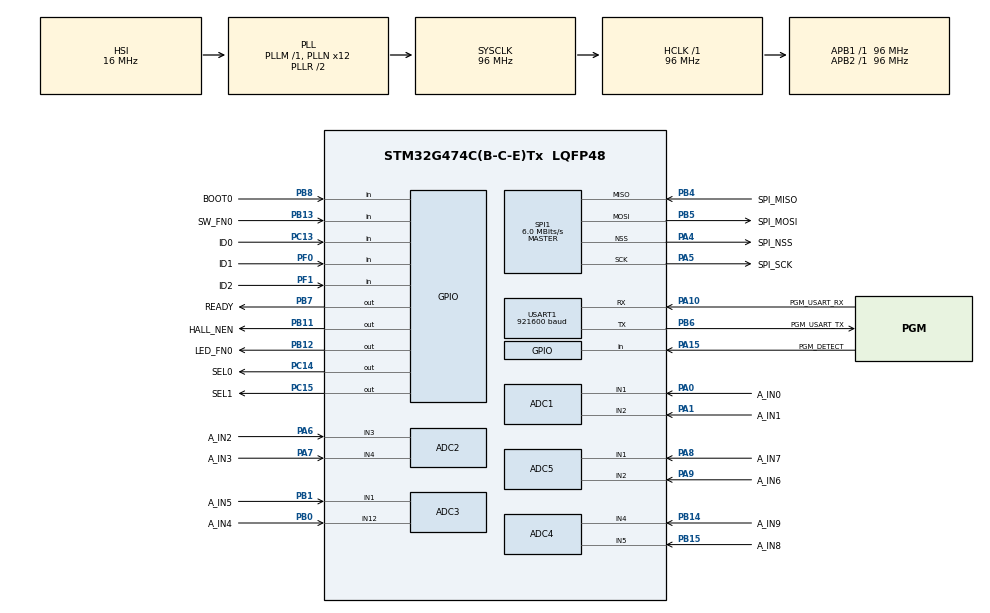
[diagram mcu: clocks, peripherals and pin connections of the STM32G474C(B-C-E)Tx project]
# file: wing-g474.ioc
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ADC1.Channel-1\#ChannelRegularConversion=ADC_CHANNEL_1
ADC1.EnableAnalogWatchDog1=false
ADC1.NbrOfConversion=1
ADC1.NbrOfConversionFlag=1
ADC1.OffsetNumber-1\#ChannelRegularConversion=ADC_OFFSET_NONE
ADC1.Rank-1\#ChannelRegularConversion=1
ADC1.SamplingTime-1\#ChannelRegularConversion=ADC_SAMPLETIME_2CYCLES_5
ADC1.master=1
ADC2.Channel-1\#ChannelRegularConversion=ADC_CHANNEL_3
ADC2.NbrOfConversionFlag=1
ADC2.OffsetNumber-1\#ChannelRegularConversion=ADC_OFFSET_NONE
ADC2.Rank-1\#ChannelRegularConversion=1
ADC2.SamplingTime-1\#ChannelRegularConversion=ADC_SAMPLETIME_2CYCLES_5
ADC3.Channel-0\#ChannelRegularConversion=ADC_CHANNEL_1
ADC3.NbrOfConversionFlag=1
ADC3.OffsetNumber-0\#ChannelRegularConversion=ADC_OFFSET_NONE
ADC3.Rank-0\#ChannelRegularConversion=1
ADC3.SamplingTime-0\#ChannelRegularConversion=ADC_SAMPLETIME_2CYCLES_5
ADC3.master=1
ADC4.Channel-0\#ChannelRegularConversion=ADC_CHANNEL_4
ADC4.NbrOfConversionFlag=1
ADC4.OffsetNumber-0\#ChannelRegularConversion=ADC_OFFSET_NONE
ADC4.Rank-0\#ChannelRegularConversion=1
ADC4.SamplingTime-0\#ChannelRegularConversion=ADC_SAMPLETIME_2CYCLES_5
ADC5.Channel-0\#ChannelRegularConversion=ADC_CHANNEL_1
ADC5.NbrOfConversionFlag=1
ADC5.OffsetNumber-0\#ChannelRegularConversion=ADC_OFFSET_NONE
ADC5.Rank-0\#ChannelRegularConversion=1
ADC5.SamplingTime-0\#ChannelRegularConversion=ADC_SAMPLETIME_2CYCLES_5
Dma.ADC1.0.Direction=DMA_PERIPH_TO_MEMORY
Dma.ADC1.0.EventEnable=DISABLE
Dma.ADC1.0.Instance=DMA1_Channel1
Dma.ADC1.0.MemDataAlignment=DMA_MDATAALIGN_HALFWORD
Dma.ADC1.0.MemInc=DMA_MINC_ENABLE
Dma.ADC1.0.Mode=DMA_CIRCULAR
Dma.ADC1.0.PeriphDataAlignment=DMA_PDATAALIGN_HALFWORD
Dma.ADC1.0.PeriphInc=DMA_PINC_DISABLE
Dma.ADC1.0.Polarity=HAL_DMAMUX_REQ_GEN_RISING
Dma.ADC1.0.Priority=DMA_PRIORITY_LOW
Dma.ADC1.0.RequestNumber=1
Dma.ADC1.0.SignalID=NONE
Dma.ADC1.0.SyncEnable=DISABLE
Dma.ADC1.0.SyncPolarity=HAL_DMAMUX_SYNC_NO_EVENT
Dma.ADC1.0.SyncRequestNumber=1
Dma.ADC1.0.SyncSignalID=NONE
Dma.ADC2.1.Direction=DMA_PERIPH_TO_MEMORY
Dma.ADC2.1.EventEnable=DISABLE
Dma.ADC2.1.Instance=DMA1_Channel2
Dma.ADC2.1.MemDataAlignment=DMA_MDATAALIGN_HALFWORD
Dma.ADC2.1.MemInc=DMA_MINC_ENABLE
Dma.ADC2.1.Mode=DMA_CIRCULAR
Dma.ADC2.1.PeriphDataAlignment=DMA_PDATAALIGN_HALFWORD
Dma.ADC2.1.PeriphInc=DMA_PINC_DISABLE
Dma.ADC2.1.Polarity=HAL_DMAMUX_REQ_GEN_RISING
Dma.ADC2.1.Priority=DMA_PRIORITY_LOW
Dma.ADC2.1.RequestNumber=1
Dma.ADC2.1.SignalID=NONE
Dma.ADC2.1.SyncEnable=DISABLE
Dma.ADC2.1.SyncPolarity=HAL_DMAMUX_SYNC_NO_EVENT
Dma.ADC2.1.SyncRequestNumber=1
Dma.ADC2.1.SyncSignalID=NONE
Dma.ADC3.2.Direction=DMA_PERIPH_TO_MEMORY
Dma.ADC3.2.EventEnable=DISABLE
Dma.ADC3.2.Instance=DMA1_Channel3
Dma.ADC3.2.MemDataAlignment=DMA_MDATAALIGN_HALFWORD
Dma.ADC3.2.MemInc=DMA_MINC_ENABLE
Dma.ADC3.2.Mode=DMA_CIRCULAR
Dma.ADC3.2.PeriphDataAlignment=DMA_PDATAALIGN_HALFWORD
Dma.ADC3.2.PeriphInc=DMA_PINC_DISABLE
Dma.ADC3.2.Polarity=HAL_DMAMUX_REQ_GEN_RISING
Dma.ADC3.2.Priority=DMA_PRIORITY_LOW
Dma.ADC3.2.RequestNumber=1
Dma.ADC3.2.SignalID=NONE
Dma.ADC3.2.SyncEnable=DISABLE
Dma.ADC3.2.SyncPolarity=HAL_DMAMUX_SYNC_NO_EVENT
Dma.ADC3.2.SyncRequestNumber=1
Dma.ADC3.2.SyncSignalID=NONE
Dma.ADC4.3.Direction=DMA_PERIPH_TO_MEMORY
Dma.ADC4.3.EventEnable=DISABLE
Dma.ADC4.3.Instance=DMA1_Channel4
Dma.ADC4.3.MemDataAlignment=DMA_MDATAALIGN_HALFWORD
Dma.ADC4.3.MemInc=DMA_MINC_ENABLE
Dma.ADC4.3.Mode=DMA_CIRCULAR
Dma.ADC4.3.PeriphDataAlignment=DMA_PDATAALIGN_HALFWORD
Dma.ADC4.3.PeriphInc=DMA_PINC_DISABLE
Dma.ADC4.3.Polarity=HAL_DMAMUX_REQ_GEN_RISING
Dma.ADC4.3.Priority=DMA_PRIORITY_LOW
Dma.ADC4.3.RequestNumber=1
Dma.ADC4.3.SignalID=NONE
Dma.ADC4.3.SyncEnable=DISABLE
Dma.ADC4.3.SyncPolarity=HAL_DMAMUX_SYNC_NO_EVENT
Dma.ADC4.3.SyncRequestNumber=1
Dma.ADC4.3.SyncSignalID=NONE
Dma.ADC5.4.Direction=DMA_PERIPH_TO_MEMORY
Dma.ADC5.4.EventEnable=DISABLE
Dma.ADC5.4.Instance=DMA1_Channel5
Dma.ADC5.4.MemDataAlignment=DMA_MDATAALIGN_HALFWORD
Dma.ADC5.4.MemInc=DMA_MINC_ENABLE
Dma.ADC5.4.Mode=DMA_CIRCULAR
Dma.ADC5.4.PeriphDataAlignment=DMA_PDATAALIGN_HALFWORD
Dma.ADC5.4.PeriphInc=DMA_PINC_DISABLE
Dma.ADC5.4.Polarity=HAL_DMAMUX_REQ_GEN_RISING
Dma.ADC5.4.Priority=DMA_PRIORITY_LOW
Dma.ADC5.4.RequestNumber=1
Dma.ADC5.4.SignalID=NONE
Dma.ADC5.4.SyncEnable=DISABLE
Dma.ADC5.4.SyncPolarity=HAL_DMAMUX_SYNC_NO_EVENT
Dma.ADC5.4.SyncRequestNumber=1
Dma.ADC5.4.SyncSignalID=NONE
Dma.Request0=ADC1
Dma.Request1=ADC2
Dma.Request2=ADC3
Dma.Request3=ADC4
Dma.Request4=ADC5
Mcu.Family=STM32G4
Mcu.Name=STM32G474C(B-C-E)Tx
Mcu.Package=LQFP48
NVIC.DMA1_Channel1_IRQn=true\:0\:0\:false\:false\:true\:false\:true\:true
NVIC.DMA1_Channel2_IRQn=true\:0\:0\:false\:false\:true\:false\:true\:true
NVIC.DMA1_Channel3_IRQn=true\:0\:0\:false\:false\:true\:false\:true\:true
NVIC.DMA1_Channel4_IRQn=true\:0\:0\:false\:false\:true\:false\:true\:true
NVIC.DMA1_Channel5_IRQn=true\:0\:0\:false\:false\:true\:false\:true\:true
NVIC.PriorityGroup=NVIC_PRIORITYGROUP_4
NVIC.USART1_IRQn=true\:0\:0\:false\:false\:true\:true\:true\:true
PA0.GPIO_Label=A_IN0
PA0.Mode=IN1-Single-Ended
PA0.Signal=ADC1_IN1
PA1.GPIO_Label=A_IN1
PA1.Mode=IN2-Single-Ended
PA1.Signal=ADC1_IN2
PA10.GPIO_Label=PGM_USART_RX
PA10.Mode=Asynchronous
PA10.Signal=USART1_RX
PA13.Mode=Trace_Asynchronous_SW
PA13.Signal=SYS_JTMS-SWDIO
PA14.Mode=Trace_Asynchronous_SW
PA14.Signal=SYS_JTCK-SWCLK
PA15.GPIO_Label=PGM_DETECT
PA15.GPIO_PuPd=GPIO_PULLUP
PA15.Signal=GPIO_Input
PA4.GPIO_Label=SPI_NSS
PA4.Mode=NSS_Signal_Hard_Output
PA4.Signal=SPI1_NSS
PA5.GPIO_Label=SPI_SCK
PA5.Mode=Full_Duplex_Master
PA5.Signal=SPI1_SCK
PA6.GPIO_Label=A_IN2
PA6.Mode=IN3-Single-Ended
PA6.Signal=ADC2_IN3
PA7.GPIO_Label=A_IN3
PA7.Mode=IN4-Single-Ended
PA7.Signal=ADC2_IN4
PA8.GPIO_Label=A_IN7
PA8.Mode=IN1-Single-Ended
PA8.Signal=ADC5_IN1
PA9.GPIO_Label=A_IN6
PA9.Mode=IN2-Single-Ended
PA9.Signal=ADC5_IN2
PB0.GPIO_Label=A_IN4
PB0.Mode=IN12-Single-Ended
PB0.Signal=ADC3_IN12
PB1.GPIO_Label=A_IN5
PB1.Mode=IN1-Single-Ended
PB1.Signal=ADC3_IN1
PB11.GPIO_Label=HALL_NEN
PB11.GPIO_ModeDefaultOutputPP=GPIO_MODE_OUTPUT_PP
PB11.GPIO_PuPd=GPIO_NOPULL
PB11.PinState=GPIO_PIN_SET
PB11.Signal=GPIO_Output
PB12.GPIO_Label=LED_FN0
PB12.Signal=GPIO_Output
PB13.GPIO_Label=SW_FN0
PB13.GPIO_PuPd=GPIO_PULLUP
PB13.Signal=GPIO_Input
PB14.GPIO_Label=A_IN9
PB14.Mode=IN4-Single-Ended
PB14.Signal=ADC4_IN4
PB15.GPIO_Label=A_IN8
PB15.Mode=IN5-Single-Ended
PB15.Signal=ADC4_IN5
PB3.Mode=Trace_Asynchronous_SW
PB3.Signal=SYS_JTDO-SWO
PB4.GPIO_Label=SPI_MISO
PB4.Mode=Full_Duplex_Master
PB4.Signal=SPI1_MISO
PB5.GPIO_Label=SPI_MOSI
PB5.Mode=Full_Duplex_Master
PB5.Signal=SPI1_MOSI
PB6.GPIO_Label=PGM_USART_TX
PB6.Mode=Asynchronous
PB6.Signal=USART1_TX
PB7.GPIO_Label=READY
PB7.Signal=GPIO_Output
PB8-BOOT0.GPIO_Label=BOOT0
PB8-BOOT0.Signal=GPIO_Input
PC13.GPIO_Label=ID0
PC13.Signal=GPIO_Input
PC14-OSC32_IN.GPIO_Label=SEL0
PC14-OSC32_IN.Signal=GPIO_Output
PC15-OSC32_OUT.GPIO_Label=SEL1
PC15-OSC32_OUT.Signal=GPIO_Output
PF0-OSC_IN.GPIO_Label=ID1
PF0-OSC_IN.Signal=GPIO_Input
PF1-OSC_OUT.GPIO_Label=ID2
PF1-OSC_OUT.Signal=GPIO_Input
ProjectManager.HeapSize=0x200
ProjectManager.StackSize=0x400
ProjectManager.TargetToolchain=CMake
RCC.ADC12Freq_Value=96000000
RCC.ADC345Freq_Value=96000000
RCC.AHBFreq_Value=96000000
RCC.APB1Freq_Value=96000000
RCC.APB1TimFreq_Value=96000000
RCC.APB2Freq_Value=96000000
RCC.APB2TimFreq_Value=96000000
RCC.CortexFreq_Value=96000000
RCC.EXTERNAL_CLOCK_VALUE=12288000
RCC.HCLKFreq_Value=96000000
RCC.HSE_VALUE=8000000
RCC.HSI48_VALUE=48000000
RCC.HSI_VALUE=16000000
RCC.LSE_VALUE=32768
RCC.PLLN=12
RCC.SYSCLKFreq_VALUE=96000000
RCC.SYSCLKSource=RCC_SYSCLKSOURCE_PLLCLK
RCC.USBFreq_Value=96000000
RCC.VCOOutputFreq_Value=192000000
SPI1.BaudRatePrescaler=SPI_BAUDRATEPRESCALER_16
SPI1.CRCCalculation=SPI_CRCCALCULATION_ENABLE
SPI1.CRCLength=SPI_CRC_LENGTH_16BIT
SPI1.CalculateBaudRate=6.0 MBits/s
SPI1.DataSize=SPI_DATASIZE_16BIT
SPI1.Direction=SPI_DIRECTION_2LINES
SPI1.Mode=SPI_MODE_MASTER
SPI1.NSSPMode=SPI_NSS_PULSE_DISABLE
SPI1.VirtualNSS=VM_NSSHARD
SPI1.VirtualType=VM_MASTER
USART1.BaudRate=921600
USART1.VirtualMode-Asynchronous=VM_ASYNC
VP_SYS_VS_DBSignals.Mode=DisableDeadBatterySignals
board=custom

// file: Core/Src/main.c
/* USER CODE BEGIN Header */
/**
  ******************************************************************************
  * @file           : main.c
  * @brief          : Main program body
  ******************************************************************************
  * @attention
  *
  * Copyright (c) 2026 STMicroelectronics.
  * All rights reserved.
  *
  * This software is licensed under terms that can be found in the LICENSE file
  * in the root directory of this software component.
  * If no LICENSE file comes with this software, it is provided AS-IS.
  *
  ******************************************************************************
  */
/* USER CODE END Header */
#include "main.h"

/* USER CODE BEGIN Includes */
#include "app/app.h"
/* USER CODE END Includes */

ADC_HandleTypeDef hadc1;
ADC_HandleTypeDef hadc2;
ADC_HandleTypeDef hadc3;
ADC_HandleTypeDef hadc4;
ADC_HandleTypeDef hadc5;
DMA_HandleTypeDef hdma_adc1;
DMA_HandleTypeDef hdma_adc2;
DMA_HandleTypeDef hdma_adc3;
DMA_HandleTypeDef hdma_adc4;
DMA_HandleTypeDef hdma_adc5;

SPI_HandleTypeDef hspi1;

UART_HandleTypeDef huart1;

void SystemClock_Config(void);
static void MX_GPIO_Init(void);
static void MX_DMA_Init(void);
static void MX_ADC1_Init(void);
static void MX_ADC2_Init(void);
static void MX_ADC3_Init(void);
static void MX_ADC4_Init(void);
static void MX_ADC5_Init(void);
static void MX_SPI1_Init(void);
static void MX_USART1_UART_Init(void);

int main(void)
{

  /* MCU Configuration--------------------------------------------------------*/

  /* Reset of all peripherals, Initializes the Flash interface and the Systick. */
  HAL_Init();

  /* Configure the system clock */
  SystemClock_Config();

  /* Initialize all configured peripherals */
  MX_GPIO_Init();
  MX_DMA_Init();
  MX_ADC1_Init();
  MX_ADC2_Init();
  MX_ADC3_Init();
  MX_ADC4_Init();
  MX_ADC5_Init();
  MX_SPI1_Init();
  MX_USART1_UART_Init();
  /* USER CODE BEGIN 2 */
  main_init();
  /* USER CODE END 2 */

  /* Infinite loop */
  while (1)
  {

    /* USER CODE BEGIN 3 */
    main_task();
  }
  /* USER CODE END 3 */
}

void SystemClock_Config(void)
{
  RCC_OscInitTypeDef RCC_OscInitStruct = {0};
  RCC_ClkInitTypeDef RCC_ClkInitStruct = {0};

  /** Configure the main internal regulator output voltage
  */
  HAL_PWREx_ControlVoltageScaling(PWR_REGULATOR_VOLTAGE_SCALE1);

  /** Initializes the RCC Oscillators according to the specified parameters
  * in the RCC_OscInitTypeDef structure.
  */
  RCC_OscInitStruct.OscillatorType = RCC_OSCILLATORTYPE_HSI;
  RCC_OscInitStruct.HSIState = RCC_HSI_ON;
  RCC_OscInitStruct.HSICalibrationValue = RCC_HSICALIBRATION_DEFAULT;
  RCC_OscInitStruct.PLL.PLLState = RCC_PLL_ON;
  RCC_OscInitStruct.PLL.PLLSource = RCC_PLLSOURCE_HSI;
  RCC_OscInitStruct.PLL.PLLM = RCC_PLLM_DIV1;
  RCC_OscInitStruct.PLL.PLLN = 12;
  RCC_OscInitStruct.PLL.PLLP = RCC_PLLP_DIV2;
  RCC_OscInitStruct.PLL.PLLQ = RCC_PLLQ_DIV2;
  RCC_OscInitStruct.PLL.PLLR = RCC_PLLR_DIV2;
  if (HAL_RCC_OscConfig(&RCC_OscInitStruct) != HAL_OK)
  {
    Error_Handler();
  }

  /** Initializes the CPU, AHB and APB buses clocks
  */
  RCC_ClkInitStruct.ClockType = RCC_CLOCKTYPE_HCLK|RCC_CLOCKTYPE_SYSCLK
                              |RCC_CLOCKTYPE_PCLK1|RCC_CLOCKTYPE_PCLK2;
  RCC_ClkInitStruct.SYSCLKSource = RCC_SYSCLKSOURCE_PLLCLK;
  RCC_ClkInitStruct.AHBCLKDivider = RCC_SYSCLK_DIV1;
  RCC_ClkInitStruct.APB1CLKDivider = RCC_HCLK_DIV1;
  RCC_ClkInitStruct.APB2CLKDivider = RCC_HCLK_DIV1;

  if (HAL_RCC_ClockConfig(&RCC_ClkInitStruct, FLASH_LATENCY_3) != HAL_OK)
  {
    Error_Handler();
  }
}

static void MX_ADC1_Init(void)
{

  ADC_MultiModeTypeDef multimode = {0};
  ADC_ChannelConfTypeDef sConfig = {0};

  /** Common config
  */
  hadc1.Instance = ADC1;
  hadc1.Init.ClockPrescaler = ADC_CLOCK_SYNC_PCLK_DIV2;
  hadc1.Init.Resolution = ADC_RESOLUTION_12B;
  hadc1.Init.DataAlign = ADC_DATAALIGN_RIGHT;
  hadc1.Init.GainCompensation = 0;
  hadc1.Init.ScanConvMode = ADC_SCAN_DISABLE;
  hadc1.Init.EOCSelection = ADC_EOC_SINGLE_CONV;
  hadc1.Init.LowPowerAutoWait = DISABLE;
  hadc1.Init.ContinuousConvMode = DISABLE;
  hadc1.Init.NbrOfConversion = 1;
  hadc1.Init.DiscontinuousConvMode = DISABLE;
  hadc1.Init.ExternalTrigConv = ADC_SOFTWARE_START;
  hadc1.Init.ExternalTrigConvEdge = ADC_EXTERNALTRIGCONVEDGE_NONE;
  hadc1.Init.DMAContinuousRequests = DISABLE;
  hadc1.Init.Overrun = ADC_OVR_DATA_PRESERVED;
  hadc1.Init.OversamplingMode = DISABLE;
  if (HAL_ADC_Init(&hadc1) != HAL_OK)
  {
    Error_Handler();
  }

  /** Configure the ADC multi-mode
  */
  multimode.Mode = ADC_MODE_INDEPENDENT;
  if (HAL_ADCEx_MultiModeConfigChannel(&hadc1, &multimode) != HAL_OK)
  {
    Error_Handler();
  }

  /** Configure Regular Channel
  */
  sConfig.Channel = ADC_CHANNEL_1;
  sConfig.Rank = ADC_REGULAR_RANK_1;
  sConfig.SamplingTime = ADC_SAMPLETIME_2CYCLES_5;
  sConfig.SingleDiff = ADC_SINGLE_ENDED;
  sConfig.OffsetNumber = ADC_OFFSET_NONE;
  sConfig.Offset = 0;
  if (HAL_ADC_ConfigChannel(&hadc1, &sConfig) != HAL_OK)
  {
    Error_Handler();
  }

}

static void MX_ADC2_Init(void)
{

  ADC_ChannelConfTypeDef sConfig = {0};

  /** Common config
  */
  hadc2.Instance = ADC2;
  hadc2.Init.ClockPrescaler = ADC_CLOCK_SYNC_PCLK_DIV2;
  hadc2.Init.Resolution = ADC_RESOLUTION_12B;
  hadc2.Init.DataAlign = ADC_DATAALIGN_RIGHT;
  hadc2.Init.GainCompensation = 0;
  hadc2.Init.ScanConvMode = ADC_SCAN_DISABLE;
  hadc2.Init.EOCSelection = ADC_EOC_SINGLE_CONV;
  hadc2.Init.LowPowerAutoWait = DISABLE;
  hadc2.Init.ContinuousConvMode = DISABLE;
  hadc2.Init.NbrOfConversion = 1;
  hadc2.Init.DiscontinuousConvMode = DISABLE;
  hadc2.Init.ExternalTrigConv = ADC_SOFTWARE_START;
  hadc2.Init.ExternalTrigConvEdge = ADC_EXTERNALTRIGCONVEDGE_NONE;
  hadc2.Init.DMAContinuousRequests = DISABLE;
  hadc2.Init.Overrun = ADC_OVR_DATA_PRESERVED;
  hadc2.Init.OversamplingMode = DISABLE;
  if (HAL_ADC_Init(&hadc2) != HAL_OK)
  {
    Error_Handler();
  }

  /** Configure Regular Channel
  */
  sConfig.Channel = ADC_CHANNEL_3;
  sConfig.Rank = ADC_REGULAR_RANK_1;
  sConfig.SamplingTime = ADC_SAMPLETIME_2CYCLES_5;
  sConfig.SingleDiff = ADC_SINGLE_ENDED;
  sConfig.OffsetNumber = ADC_OFFSET_NONE;
  sConfig.Offset = 0;
  if (HAL_ADC_ConfigChannel(&hadc2, &sConfig) != HAL_OK)
  {
    Error_Handler();
  }

}

static void MX_ADC3_Init(void)
{

  ADC_MultiModeTypeDef multimode = {0};
  ADC_ChannelConfTypeDef sConfig = {0};

  /** Common config
  */
  hadc3.Instance = ADC3;
  hadc3.Init.ClockPrescaler = ADC_CLOCK_SYNC_PCLK_DIV2;
  hadc3.Init.Resolution = ADC_RESOLUTION_12B;
  hadc3.Init.DataAlign = ADC_DATAALIGN_RIGHT;
  hadc3.Init.GainCompensation = 0;
  hadc3.Init.ScanConvMode = ADC_SCAN_DISABLE;
  hadc3.Init.EOCSelection = ADC_EOC_SINGLE_CONV;
  hadc3.Init.LowPowerAutoWait = DISABLE;
  hadc3.Init.ContinuousConvMode = DISABLE;
  hadc3.Init.NbrOfConversion = 1;
  hadc3.Init.DiscontinuousConvMode = DISABLE;
  hadc3.Init.ExternalTrigConv = ADC_SOFTWARE_START;
  hadc3.Init.ExternalTrigConvEdge = ADC_EXTERNALTRIGCONVEDGE_NONE;
  hadc3.Init.DMAContinuousRequests = DISABLE;
  hadc3.Init.Overrun = ADC_OVR_DATA_PRESERVED;
  hadc3.Init.OversamplingMode = DISABLE;
  if (HAL_ADC_Init(&hadc3) != HAL_OK)
  {
    Error_Handler();
  }

  /** Configure the ADC multi-mode
  */
  multimode.Mode = ADC_MODE_INDEPENDENT;
  if (HAL_ADCEx_MultiModeConfigChannel(&hadc3, &multimode) != HAL_OK)
  {
    Error_Handler();
  }

  /** Configure Regular Channel
  */
  sConfig.Channel = ADC_CHANNEL_1;
  sConfig.Rank = ADC_REGULAR_RANK_1;
  sConfig.SamplingTime = ADC_SAMPLETIME_2CYCLES_5;
  sConfig.SingleDiff = ADC_SINGLE_ENDED;
  sConfig.OffsetNumber = ADC_OFFSET_NONE;
  sConfig.Offset = 0;
  if (HAL_ADC_ConfigChannel(&hadc3, &sConfig) != HAL_OK)
  {
    Error_Handler();
  }

}

static void MX_ADC4_Init(void)
{

  ADC_ChannelConfTypeDef sConfig = {0};

  /** Common config
  */
  hadc4.Instance = ADC4;
  hadc4.Init.ClockPrescaler = ADC_CLOCK_SYNC_PCLK_DIV2;
  hadc4.Init.Resolution = ADC_RESOLUTION_12B;
  hadc4.Init.DataAlign = ADC_DATAALIGN_RIGHT;
  hadc4.Init.GainCompensation = 0;
  hadc4.Init.ScanConvMode = ADC_SCAN_DISABLE;
  hadc4.Init.EOCSelection = ADC_EOC_SINGLE_CONV;
  hadc4.Init.LowPowerAutoWait = DISABLE;
  hadc4.Init.ContinuousConvMode = DISABLE;
  hadc4.Init.NbrOfConversion = 1;
  hadc4.Init.DiscontinuousConvMode = DISABLE;
  hadc4.Init.ExternalTrigConv = ADC_SOFTWARE_START;
  hadc4.Init.ExternalTrigConvEdge = ADC_EXTERNALTRIGCONVEDGE_NONE;
  hadc4.Init.DMAContinuousRequests = DISABLE;
  hadc4.Init.Overrun = ADC_OVR_DATA_PRESERVED;
  hadc4.Init.OversamplingMode = DISABLE;
  if (HAL_ADC_Init(&hadc4) != HAL_OK)
  {
    Error_Handler();
  }

  /** Configure Regular Channel
  */
  sConfig.Channel = ADC_CHANNEL_4;
  sConfig.Rank = ADC_REGULAR_RANK_1;
  sConfig.SamplingTime = ADC_SAMPLETIME_2CYCLES_5;
  sConfig.SingleDiff = ADC_SINGLE_ENDED;
  sConfig.OffsetNumber = ADC_OFFSET_NONE;
  sConfig.Offset = 0;
  if (HAL_ADC_ConfigChannel(&hadc4, &sConfig) != HAL_OK)
  {
    Error_Handler();
  }

}

static void MX_ADC5_Init(void)
{

  ADC_ChannelConfTypeDef sConfig = {0};

  /** Common config
  */
  hadc5.Instance = ADC5;
  hadc5.Init.ClockPrescaler = ADC_CLOCK_SYNC_PCLK_DIV2;
  hadc5.Init.Resolution = ADC_RESOLUTION_12B;
  hadc5.Init.DataAlign = ADC_DATAALIGN_RIGHT;
  hadc5.Init.GainCompensation = 0;
  hadc5.Init.ScanConvMode = ADC_SCAN_DISABLE;
  hadc5.Init.EOCSelection = ADC_EOC_SINGLE_CONV;
  hadc5.Init.LowPowerAutoWait = DISABLE;
  hadc5.Init.ContinuousConvMode = DISABLE;
  hadc5.Init.NbrOfConversion = 1;
  hadc5.Init.DiscontinuousConvMode = DISABLE;
  hadc5.Init.ExternalTrigConv = ADC_SOFTWARE_START;
  hadc5.Init.ExternalTrigConvEdge = ADC_EXTERNALTRIGCONVEDGE_NONE;
  hadc5.Init.DMAContinuousRequests = DISABLE;
  hadc5.Init.Overrun = ADC_OVR_DATA_PRESERVED;
  hadc5.Init.OversamplingMode = DISABLE;
  if (HAL_ADC_Init(&hadc5) != HAL_OK)
  {
    Error_Handler();
  }

  /** Configure Regular Channel
  */
  sConfig.Channel = ADC_CHANNEL_1;
  sConfig.Rank = ADC_REGULAR_RANK_1;
  sConfig.SamplingTime = ADC_SAMPLETIME_2CYCLES_5;
  sConfig.SingleDiff = ADC_SINGLE_ENDED;
  sConfig.OffsetNumber = ADC_OFFSET_NONE;
  sConfig.Offset = 0;
  if (HAL_ADC_ConfigChannel(&hadc5, &sConfig) != HAL_OK)
  {
    Error_Handler();
  }

}

static void MX_SPI1_Init(void)
{

  /* SPI1 parameter configuration*/
  hspi1.Instance = SPI1;
  hspi1.Init.Mode = SPI_MODE_MASTER;
  hspi1.Init.Direction = SPI_DIRECTION_2LINES;
  hspi1.Init.DataSize = SPI_DATASIZE_16BIT;
  hspi1.Init.CLKPolarity = SPI_POLARITY_LOW;
  hspi1.Init.CLKPhase = SPI_PHASE_1EDGE;
  hspi1.Init.NSS = SPI_NSS_HARD_OUTPUT;
  hspi1.Init.BaudRatePrescaler = SPI_BAUDRATEPRESCALER_16;
  hspi1.Init.FirstBit = SPI_FIRSTBIT_MSB;
  hspi1.Init.TIMode = SPI_TIMODE_DISABLE;
  hspi1.Init.CRCCalculation = SPI_CRCCALCULATION_ENABLE;
  hspi1.Init.CRCPolynomial = 7;
  hspi1.Init.CRCLength = SPI_CRC_LENGTH_16BIT;
  hspi1.Init.NSSPMode = SPI_NSS_PULSE_DISABLE;
  if (HAL_SPI_Init(&hspi1) != HAL_OK)
  {
    Error_Handler();
  }

}

static void MX_USART1_UART_Init(void)
{

  huart1.Instance = USART1;
  huart1.Init.BaudRate = 921600;
  huart1.Init.WordLength = UART_WORDLENGTH_8B;
  huart1.Init.StopBits = UART_STOPBITS_1;
  huart1.Init.Parity = UART_PARITY_NONE;
  huart1.Init.Mode = UART_MODE_TX_RX;
  huart1.Init.HwFlowCtl = UART_HWCONTROL_NONE;
  huart1.Init.OverSampling = UART_OVERSAMPLING_16;
  huart1.Init.OneBitSampling = UART_ONE_BIT_SAMPLE_DISABLE;
  huart1.Init.ClockPrescaler = UART_PRESCALER_DIV1;
  huart1.AdvancedInit.AdvFeatureInit = UART_ADVFEATURE_NO_INIT;
  if (HAL_UART_Init(&huart1) != HAL_OK)
  {
    Error_Handler();
  }
  if (HAL_UARTEx_SetTxFifoThreshold(&huart1, UART_TXFIFO_THRESHOLD_1_8) != HAL_OK)
  {
    Error_Handler();
  }
  if (HAL_UARTEx_SetRxFifoThreshold(&huart1, UART_RXFIFO_THRESHOLD_1_8) != HAL_OK)
  {
    Error_Handler();
  }
  if (HAL_UARTEx_DisableFifoMode(&huart1) != HAL_OK)
  {
    Error_Handler();
  }

}

static void MX_DMA_Init(void)
{

  /* DMA controller clock enable */
  __HAL_RCC_DMAMUX1_CLK_ENABLE();
  __HAL_RCC_DMA1_CLK_ENABLE();

  /* DMA interrupt init */
  /* DMA1_Channel1_IRQn interrupt configuration */
  HAL_NVIC_SetPriority(DMA1_Channel1_IRQn, 0, 0);
  HAL_NVIC_EnableIRQ(DMA1_Channel1_IRQn);
  /* DMA1_Channel2_IRQn interrupt configuration */
  HAL_NVIC_SetPriority(DMA1_Channel2_IRQn, 0, 0);
  HAL_NVIC_EnableIRQ(DMA1_Channel2_IRQn);
  /* DMA1_Channel3_IRQn interrupt configuration */
  HAL_NVIC_SetPriority(DMA1_Channel3_IRQn, 0, 0);
  HAL_NVIC_EnableIRQ(DMA1_Channel3_IRQn);
  /* DMA1_Channel4_IRQn interrupt configuration */
  HAL_NVIC_SetPriority(DMA1_Channel4_IRQn, 0, 0);
  HAL_NVIC_EnableIRQ(DMA1_Channel4_IRQn);
  /* DMA1_Channel5_IRQn interrupt configuration */
  HAL_NVIC_SetPriority(DMA1_Channel5_IRQn, 0, 0);
  HAL_NVIC_EnableIRQ(DMA1_Channel5_IRQn);

}

static void MX_GPIO_Init(void)
{
  GPIO_InitTypeDef GPIO_InitStruct = {0};

  /* GPIO Ports Clock Enable */
  __HAL_RCC_GPIOC_CLK_ENABLE();
  __HAL_RCC_GPIOF_CLK_ENABLE();
  __HAL_RCC_GPIOA_CLK_ENABLE();
  __HAL_RCC_GPIOB_CLK_ENABLE();

  /*Configure GPIO pin Output Level */
  HAL_GPIO_WritePin(GPIOC, SEL0_Pin|SEL1_Pin, GPIO_PIN_RESET);

  /*Configure GPIO pin Output Level */
  HAL_GPIO_WritePin(HALL_NEN_GPIO_Port, HALL_NEN_Pin, GPIO_PIN_SET);

  /*Configure GPIO pin Output Level */
  HAL_GPIO_WritePin(GPIOB, LED_FN0_Pin|READY_Pin, GPIO_PIN_RESET);

  /*Configure GPIO pin : ID0_Pin */
  GPIO_InitStruct.Pin = ID0_Pin;
  GPIO_InitStruct.Mode = GPIO_MODE_INPUT;
  GPIO_InitStruct.Pull = GPIO_NOPULL;
  HAL_GPIO_Init(ID0_GPIO_Port, &GPIO_InitStruct);

  /*Configure GPIO pins : SEL0_Pin SEL1_Pin */
  GPIO_InitStruct.Pin = SEL0_Pin|SEL1_Pin;
  GPIO_InitStruct.Mode = GPIO_MODE_OUTPUT_PP;
  GPIO_InitStruct.Pull = GPIO_NOPULL;
  GPIO_InitStruct.Speed = GPIO_SPEED_FREQ_LOW;
  HAL_GPIO_Init(GPIOC, &GPIO_InitStruct);

  /*Configure GPIO pins : ID1_Pin ID2_Pin */
  GPIO_InitStruct.Pin = ID1_Pin|ID2_Pin;
  GPIO_InitStruct.Mode = GPIO_MODE_INPUT;
  GPIO_InitStruct.Pull = GPIO_NOPULL;
  HAL_GPIO_Init(GPIOF, &GPIO_InitStruct);

  /*Configure GPIO pins : HALL_NEN_Pin LED_FN0_Pin READY_Pin */
  GPIO_InitStruct.Pin = HALL_NEN_Pin|LED_FN0_Pin|READY_Pin;
  GPIO_InitStruct.Mode = GPIO_MODE_OUTPUT_PP;
  GPIO_InitStruct.Pull = GPIO_NOPULL;
  GPIO_InitStruct.Speed = GPIO_SPEED_FREQ_LOW;
  HAL_GPIO_Init(GPIOB, &GPIO_InitStruct);

  /*Configure GPIO pin : SW_FN0_Pin */
  GPIO_InitStruct.Pin = SW_FN0_Pin;
  GPIO_InitStruct.Mode = GPIO_MODE_INPUT;
  GPIO_InitStruct.Pull = GPIO_PULLUP;
  HAL_GPIO_Init(SW_FN0_GPIO_Port, &GPIO_InitStruct);

  /*Configure GPIO pin : PGM_DETECT_Pin */
  GPIO_InitStruct.Pin = PGM_DETECT_Pin;
  GPIO_InitStruct.Mode = GPIO_MODE_INPUT;
  GPIO_InitStruct.Pull = GPIO_PULLUP;
  HAL_GPIO_Init(PGM_DETECT_GPIO_Port, &GPIO_InitStruct);

  /*Configure GPIO pin : BOOT0_Pin */
  GPIO_InitStruct.Pin = BOOT0_Pin;
  GPIO_InitStruct.Mode = GPIO_MODE_INPUT;
  GPIO_InitStruct.Pull = GPIO_NOPULL;
  HAL_GPIO_Init(BOOT0_GPIO_Port, &GPIO_InitStruct);

}

void Error_Handler(void)
{
  __disable_irq();
  while (1)
  {
  }
}
